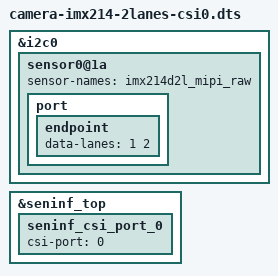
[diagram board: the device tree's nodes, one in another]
// SPDX-License-Identifier: GPL-2.0
/*
 * Copyright (c) 2023 MediaTek Inc.
 *
 */

/dts-v1/;
/plugin/;

#include "camera-imx214-csi0.dts"

/ {
	fragment@9 {
		target = <&i2c0>;
		__overlay__ {
			sensor0@1a {
				sensor-names = "imx214d2l_mipi_raw";

				port {
					endpoint {
						data-lanes = <1 2>;
					};
				};

			};
		};
	};

	fragment@10 {
		target = <&seninf_top>;
		__overlay__ {
			seninf_csi_port_0 {
				csi-port = "0";
			};
		};
	};
};
